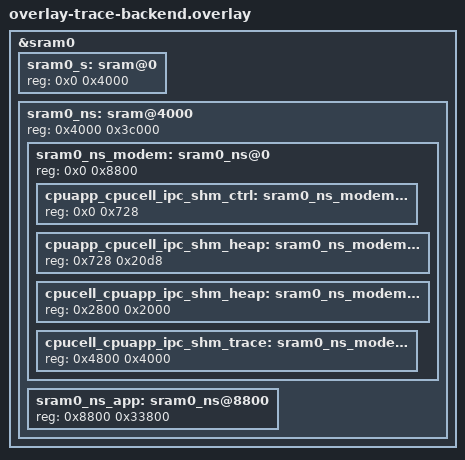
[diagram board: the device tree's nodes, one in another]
/*
 * Copyright (c) 2026 Nordic Semiconductor ASA
 *
 * SPDX-License-Identifier: LicenseRef-Nordic-5-Clause
 *
 */

/*
 * Application SRAM layout for nRF9151 DK with modem traces:
 *
 * 0x2000_4000  Non-secure RAM area          ( 240 kB)
 *   0x2000_4000  Modem shared area          (  34 kB)
 *     0x2000_4000  control                  (1832 B)
 *     0x2000_4728  app -> cell              (8408 B)
 *     0x2000_6000  cell -> app              (   8 kB)
 *     0x2000_8800  trace                    ( 16 kB)
 *   0x2000_c800  Application RAM            ( 206 kB)
 */

/delete-node/ &sram0_s;
/delete-node/ &sram0_ns;

&sram0 {

	sram0_s: sram@0 {
		reg = <0x0 0x4000>;
	};

	sram0_ns: sram@4000 {
		reg = <0x4000 0x3c000>;
		#address-cells = <1>;
		#size-cells = <1>;
		ranges = <0x0 0x4000 0x3c000>;

		/* Must be in first 128 kB of RAM. */
		sram0_ns_modem: sram0_ns@0 {
			/* Modem (shared) memory */
			reg = <0x0 0x8800>;
			#address-cells = <1>;
			#size-cells = <1>;
			ranges = <0x0 0x0 0x8800>;

			cpuapp_cpucell_ipc_shm_ctrl: sram0_ns_modem@0 {
				/* Modem IPC control */
				reg = <0x0 0x728>;
			};

			cpuapp_cpucell_ipc_shm_heap: sram0_ns_modem@728 {
				/* Modem IPC transmit */
				reg = <0x728 0x20d8>;
			};

			cpucell_cpuapp_ipc_shm_heap: sram0_ns_modem@2800 {
				/* Modem IPC receive */
				reg = <0x2800 0x2000>;
			};

			cpucell_cpuapp_ipc_shm_trace: sram0_ns_modem@4800 {
				/* Modem trace memory */
				reg = <0x4800 0x4000>;
			};

		};

		sram0_ns_app: sram0_ns@8800 {
			/* Non-Secure application memory */
			reg = <0x8800 0x33800>;
		};
	};
};
